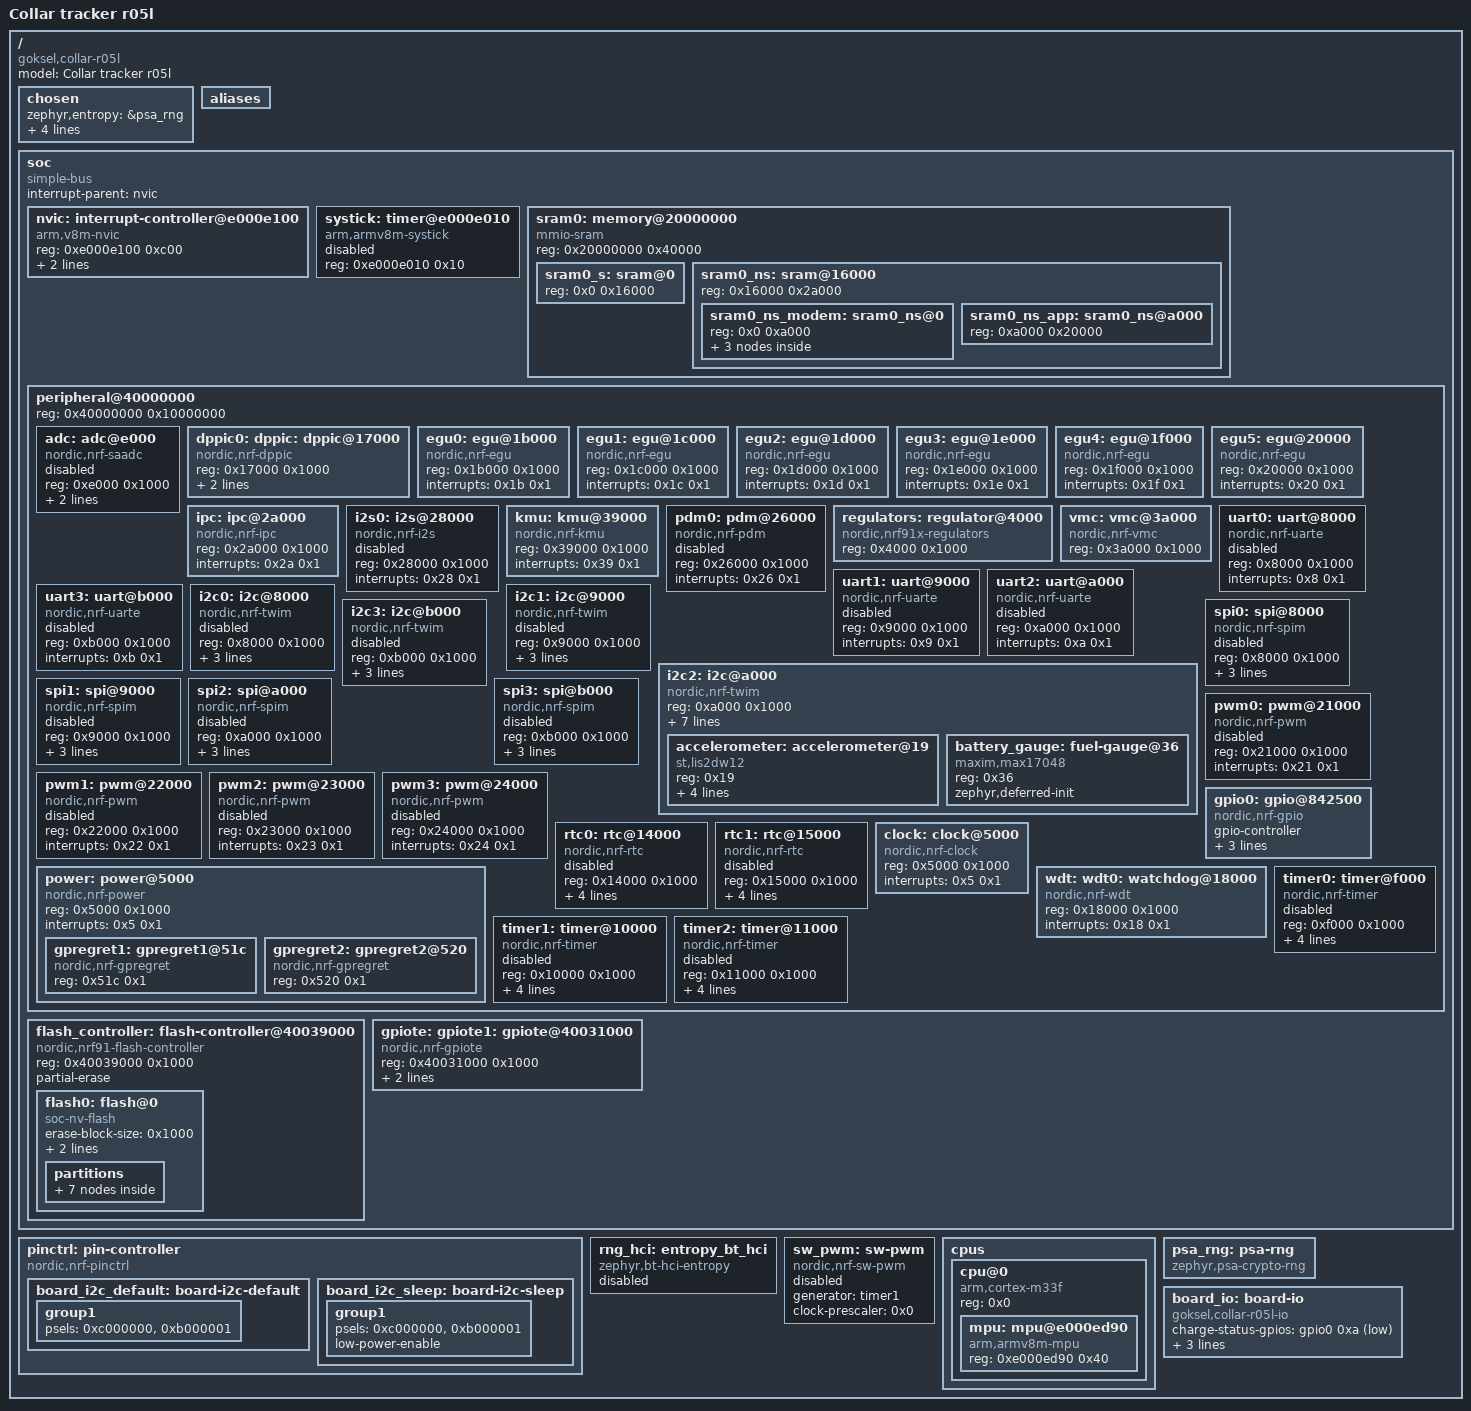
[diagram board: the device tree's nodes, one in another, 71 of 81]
/dts-v1/;

/* node '/' defined in zephyr/dts/common/skeleton.dtsi:9 */
/ {
	#address-cells = < 0x1 >;          /* in zephyr/dts/common/skeleton.dtsi:10 */
	#size-cells = < 0x1 >;             /* in zephyr/dts/common/skeleton.dtsi:11 */
	model = "Collar tracker r05l";     /* in ../../../../../Users/gok/codex/projects/collar-tracker/firmware/boards/goksel/collar_tracker_r05l/collar_tracker_r05l_nrf9151_ns.dts:7 */
	compatible = "goksel,collar-r05l"; /* in ../../../../../Users/gok/codex/projects/collar-tracker/firmware/boards/goksel/collar_tracker_r05l/collar_tracker_r05l_nrf9151_ns.dts:8 */

	/* node '/chosen' defined in zephyr/dts/common/skeleton.dtsi:13 */
	chosen {
		zephyr,entropy = &psa_rng;                   /* in zephyr/dts/arm/nordic/nrf91_ns.dtsi:31 */
		zephyr,flash-controller = &flash_controller; /* in zephyr/dts/arm/nordic/nrf91_ns.dtsi:32 */
		zephyr,sram = &sram0_ns_app;                 /* in ../../../../../Users/gok/codex/projects/collar-tracker/firmware/boards/goksel/collar_tracker_r05l/collar_tracker_r05l_nrf9151_ns.dts:10 */
		zephyr,code-partition = &slot0_ns_partition; /* in ../../../../../Users/gok/codex/projects/collar-tracker/firmware/boards/goksel/collar_tracker_r05l/collar_tracker_r05l_nrf9151_ns.dts:11 */
		zephyr,flash = &flash0;                      /* in ../../../../../Users/gok/codex/projects/collar-tracker/firmware/boards/goksel/collar_tracker_r05l/collar_tracker_r05l_nrf9151_ns.dts:12 */
	};

	/* node '/aliases' defined in zephyr/dts/common/skeleton.dtsi:15 */
	aliases {
	};

	/* node '/soc' defined in zephyr/dts/arm/armv8-m.dtsi:6 */
	soc {
		#address-cells = < 0x1 >;     /* in zephyr/dts/arm/armv8-m.dtsi:7 */
		#size-cells = < 0x1 >;        /* in zephyr/dts/arm/armv8-m.dtsi:8 */
		interrupt-parent = < &nvic >; /* in zephyr/dts/arm/armv8-m.dtsi:10 */
		ranges;                       /* in zephyr/dts/arm/armv8-m.dtsi:11 */
		compatible = "simple-bus";    /* in zephyr/dts/arm/nordic/nrf91_ns.dtsi:36 */

		/* node '/soc/interrupt-controller@e000e100' defined in zephyr/dts/arm/armv8-m.dtsi:13 */
		nvic: interrupt-controller@e000e100 {
			#address-cells = < 0x1 >;            /* in zephyr/dts/arm/armv8-m.dtsi:14 */
			compatible = "arm,v8m-nvic";         /* in zephyr/dts/arm/armv8-m.dtsi:15 */
			reg = < 0xe000e100 0xc00 >;          /* in zephyr/dts/arm/armv8-m.dtsi:16 */
			interrupt-controller;                /* in zephyr/dts/arm/armv8-m.dtsi:17 */
			#interrupt-cells = < 0x2 >;          /* in zephyr/dts/arm/armv8-m.dtsi:18 */
			arm,num-irq-priority-bits = < 0x3 >; /* in zephyr/dts/arm/nordic/nrf91_ns.dtsi:95 */
			phandle = < 0x1 >;                   /* in zephyr/dts/arm/armv8-m.dtsi:10 */
		};

		/* node '/soc/timer@e000e010' defined in zephyr/dts/arm/armv8-m.dtsi:21 */
		systick: timer@e000e010 {
			compatible = "arm,armv8m-systick"; /* in zephyr/dts/arm/armv8-m.dtsi:22 */
			reg = < 0xe000e010 0x10 >;         /* in zephyr/dts/arm/armv8-m.dtsi:23 */
			status = "disabled";               /* in zephyr/dts/arm/nordic/nrf91_ns.dtsi:100 */
		};

		/* node '/soc/memory@20000000' defined in zephyr/dts/arm/nordic/nrf91_ns.dtsi:38 */
		sram0: memory@20000000 {
			compatible = "mmio-sram";            /* in zephyr/dts/arm/nordic/nrf91_ns.dtsi:39 */
			#address-cells = < 0x1 >;            /* in zephyr/dts/arm/nordic/nrf91_ns.dtsi:40 */
			#size-cells = < 0x1 >;               /* in zephyr/dts/arm/nordic/nrf91_ns.dtsi:41 */
			reg = < 0x20000000 0x40000 >;        /* in zephyr/dts/arm/nordic/nrf9151_ns_laca.dtsi:11 */
			ranges = < 0x0 0x20000000 0x40000 >; /* in zephyr/dts/arm/nordic/nrf9151_ns_laca.dtsi:12 */

			/* node '/soc/memory@20000000/sram@0' defined in ../../../../../Users/gok/codex/projects/collar-tracker/firmware/boards/goksel/collar_tracker_r05l/collar-memory.dtsi:69 */
			sram0_s: sram@0 {
				reg = < 0x0 0x16000 >; /* in ../../../../../Users/gok/codex/projects/collar-tracker/firmware/boards/goksel/collar_tracker_r05l/collar-memory.dtsi:71 */
			};

			/* node '/soc/memory@20000000/sram@16000' defined in ../../../../../Users/gok/codex/projects/collar-tracker/firmware/boards/goksel/collar_tracker_r05l/collar-memory.dtsi:74 */
			sram0_ns: sram@16000 {
				reg = < 0x16000 0x2a000 >;        /* in ../../../../../Users/gok/codex/projects/collar-tracker/firmware/boards/goksel/collar_tracker_r05l/collar-memory.dtsi:76 */
				#address-cells = < 0x1 >;         /* in ../../../../../Users/gok/codex/projects/collar-tracker/firmware/boards/goksel/collar_tracker_r05l/collar-memory.dtsi:77 */
				#size-cells = < 0x1 >;            /* in ../../../../../Users/gok/codex/projects/collar-tracker/firmware/boards/goksel/collar_tracker_r05l/collar-memory.dtsi:78 */
				ranges = < 0x0 0x16000 0x2a000 >; /* in ../../../../../Users/gok/codex/projects/collar-tracker/firmware/boards/goksel/collar_tracker_r05l/collar-memory.dtsi:79 */

				/* node '/soc/memory@20000000/sram@16000/sram0_ns@0' defined in ../../../../../Users/gok/codex/projects/collar-tracker/firmware/boards/goksel/collar_tracker_r05l/collar-memory.dtsi:81 */
				sram0_ns_modem: sram0_ns@0 {
					reg = < 0x0 0xa000 >;        /* in ../../../../../Users/gok/codex/projects/collar-tracker/firmware/boards/goksel/collar_tracker_r05l/collar-memory.dtsi:83 */
					#address-cells = < 0x1 >;    /* in ../../../../../Users/gok/codex/projects/collar-tracker/firmware/boards/goksel/collar_tracker_r05l/collar-memory.dtsi:84 */
					#size-cells = < 0x1 >;       /* in ../../../../../Users/gok/codex/projects/collar-tracker/firmware/boards/goksel/collar_tracker_r05l/collar-memory.dtsi:85 */
					ranges = < 0x0 0x0 0xa000 >; /* in ../../../../../Users/gok/codex/projects/collar-tracker/firmware/boards/goksel/collar_tracker_r05l/collar-memory.dtsi:86 */

					/* node '/soc/memory@20000000/sram@16000/sram0_ns@0/sram0_ns_modem@0' defined in ../../../../../Users/gok/codex/projects/collar-tracker/firmware/boards/goksel/collar_tracker_r05l/collar-memory.dtsi:88 */
					cpuapp_cpucell_ipc_shm_ctrl: sram0_ns_modem@0 {
						reg = < 0x0 0x4e8 >; /* in ../../../../../Users/gok/codex/projects/collar-tracker/firmware/boards/goksel/collar_tracker_r05l/collar-memory.dtsi:90 */
					};

					/* node '/soc/memory@20000000/sram@16000/sram0_ns@0/sram0_ns_modem@4e8' defined in ../../../../../Users/gok/codex/projects/collar-tracker/firmware/boards/goksel/collar_tracker_r05l/collar-memory.dtsi:93 */
					cpuapp_cpucell_ipc_shm_heap: sram0_ns_modem@4e8 {
						reg = < 0x4e8 0x2080 >; /* in ../../../../../Users/gok/codex/projects/collar-tracker/firmware/boards/goksel/collar_tracker_r05l/collar-memory.dtsi:95 */
					};

					/* node '/soc/memory@20000000/sram@16000/sram0_ns@0/sram0_ns_modem@2568' defined in ../../../../../Users/gok/codex/projects/collar-tracker/firmware/boards/goksel/collar_tracker_r05l/collar-memory.dtsi:98 */
					cpucell_cpuapp_ipc_shm_heap: sram0_ns_modem@2568 {
						reg = < 0x2568 0x2000 >; /* in ../../../../../Users/gok/codex/projects/collar-tracker/firmware/boards/goksel/collar_tracker_r05l/collar-memory.dtsi:100 */
					};
				};

				/* node '/soc/memory@20000000/sram@16000/sram0_ns@a000' defined in ../../../../../Users/gok/codex/projects/collar-tracker/firmware/boards/goksel/collar_tracker_r05l/collar-memory.dtsi:104 */
				sram0_ns_app: sram0_ns@a000 {
					reg = < 0xa000 0x20000 >; /* in ../../../../../Users/gok/codex/projects/collar-tracker/firmware/boards/goksel/collar_tracker_r05l/collar-memory.dtsi:106 */
				};
			};
		};

		/* node '/soc/peripheral@40000000' defined in zephyr/dts/arm/nordic/nrf91_ns.dtsi:44 */
		peripheral@40000000 {
			#address-cells = < 0x1 >;               /* in zephyr/dts/arm/nordic/nrf91_ns.dtsi:45 */
			#size-cells = < 0x1 >;                  /* in zephyr/dts/arm/nordic/nrf91_ns.dtsi:46 */
			reg = < 0x40000000 0x10000000 >;        /* in zephyr/dts/arm/nordic/nrf91_ns.dtsi:47 */
			ranges = < 0x0 0x40000000 0x10000000 >; /* in zephyr/dts/arm/nordic/nrf91_ns.dtsi:48 */

			/* node '/soc/peripheral@40000000/adc@e000' defined in zephyr/dts/arm/nordic/nrf91_peripherals.dtsi:7 */
			adc: adc@e000 {
				compatible = "nordic,nrf-saadc"; /* in zephyr/dts/arm/nordic/nrf91_peripherals.dtsi:8 */
				reg = < 0xe000 0x1000 >;         /* in zephyr/dts/arm/nordic/nrf91_peripherals.dtsi:9 */
				interrupts = < 0xe 0x1 >;        /* in zephyr/dts/arm/nordic/nrf91_peripherals.dtsi:10 */
				status = "disabled";             /* in zephyr/dts/arm/nordic/nrf91_peripherals.dtsi:11 */
				#io-channel-cells = < 0x1 >;     /* in zephyr/dts/arm/nordic/nrf91_peripherals.dtsi:12 */
				zephyr,pm-device-runtime-auto;   /* in zephyr/dts/arm/nordic/nrf91_peripherals.dtsi:13 */
			};

			/* node '/soc/peripheral@40000000/dppic@17000' defined in zephyr/dts/arm/nordic/nrf91_peripherals.dtsi:16 */
			dppic0: dppic: dppic@17000 {
				compatible = "nordic,nrf-dppic"; /* in zephyr/dts/arm/nordic/nrf91_peripherals.dtsi:17 */
				reg = < 0x17000 0x1000 >;        /* in zephyr/dts/arm/nordic/nrf91_peripherals.dtsi:18 */
				status = "okay";                 /* in zephyr/dts/arm/nordic/nrf91_peripherals.dtsi:19 */
				channels = < 0x10 >;             /* in zephyr/dts/arm/nordic/nrf91_peripherals.dtsi:20 */
				groups = < 0x6 >;                /* in zephyr/dts/arm/nordic/nrf91_peripherals.dtsi:21 */
			};

			/* node '/soc/peripheral@40000000/egu@1b000' defined in zephyr/dts/arm/nordic/nrf91_peripherals.dtsi:24 */
			egu0: egu@1b000 {
				compatible = "nordic,nrf-egu"; /* in zephyr/dts/arm/nordic/nrf91_peripherals.dtsi:25 */
				reg = < 0x1b000 0x1000 >;      /* in zephyr/dts/arm/nordic/nrf91_peripherals.dtsi:26 */
				interrupts = < 0x1b 0x1 >;     /* in zephyr/dts/arm/nordic/nrf91_peripherals.dtsi:27 */
				status = "okay";               /* in zephyr/dts/arm/nordic/nrf91_peripherals.dtsi:28 */
			};

			/* node '/soc/peripheral@40000000/egu@1c000' defined in zephyr/dts/arm/nordic/nrf91_peripherals.dtsi:31 */
			egu1: egu@1c000 {
				compatible = "nordic,nrf-egu"; /* in zephyr/dts/arm/nordic/nrf91_peripherals.dtsi:32 */
				reg = < 0x1c000 0x1000 >;      /* in zephyr/dts/arm/nordic/nrf91_peripherals.dtsi:33 */
				interrupts = < 0x1c 0x1 >;     /* in zephyr/dts/arm/nordic/nrf91_peripherals.dtsi:34 */
				status = "okay";               /* in zephyr/dts/arm/nordic/nrf91_peripherals.dtsi:35 */
			};

			/* node '/soc/peripheral@40000000/egu@1d000' defined in zephyr/dts/arm/nordic/nrf91_peripherals.dtsi:38 */
			egu2: egu@1d000 {
				compatible = "nordic,nrf-egu"; /* in zephyr/dts/arm/nordic/nrf91_peripherals.dtsi:39 */
				reg = < 0x1d000 0x1000 >;      /* in zephyr/dts/arm/nordic/nrf91_peripherals.dtsi:40 */
				interrupts = < 0x1d 0x1 >;     /* in zephyr/dts/arm/nordic/nrf91_peripherals.dtsi:41 */
				status = "okay";               /* in zephyr/dts/arm/nordic/nrf91_peripherals.dtsi:42 */
			};

			/* node '/soc/peripheral@40000000/egu@1e000' defined in zephyr/dts/arm/nordic/nrf91_peripherals.dtsi:45 */
			egu3: egu@1e000 {
				compatible = "nordic,nrf-egu"; /* in zephyr/dts/arm/nordic/nrf91_peripherals.dtsi:46 */
				reg = < 0x1e000 0x1000 >;      /* in zephyr/dts/arm/nordic/nrf91_peripherals.dtsi:47 */
				interrupts = < 0x1e 0x1 >;     /* in zephyr/dts/arm/nordic/nrf91_peripherals.dtsi:48 */
				status = "okay";               /* in zephyr/dts/arm/nordic/nrf91_peripherals.dtsi:49 */
			};

			/* node '/soc/peripheral@40000000/egu@1f000' defined in zephyr/dts/arm/nordic/nrf91_peripherals.dtsi:52 */
			egu4: egu@1f000 {
				compatible = "nordic,nrf-egu"; /* in zephyr/dts/arm/nordic/nrf91_peripherals.dtsi:53 */
				reg = < 0x1f000 0x1000 >;      /* in zephyr/dts/arm/nordic/nrf91_peripherals.dtsi:54 */
				interrupts = < 0x1f 0x1 >;     /* in zephyr/dts/arm/nordic/nrf91_peripherals.dtsi:55 */
				status = "okay";               /* in zephyr/dts/arm/nordic/nrf91_peripherals.dtsi:56 */
			};

			/* node '/soc/peripheral@40000000/egu@20000' defined in zephyr/dts/arm/nordic/nrf91_peripherals.dtsi:59 */
			egu5: egu@20000 {
				compatible = "nordic,nrf-egu"; /* in zephyr/dts/arm/nordic/nrf91_peripherals.dtsi:60 */
				reg = < 0x20000 0x1000 >;      /* in zephyr/dts/arm/nordic/nrf91_peripherals.dtsi:61 */
				interrupts = < 0x20 0x1 >;     /* in zephyr/dts/arm/nordic/nrf91_peripherals.dtsi:62 */
				status = "okay";               /* in zephyr/dts/arm/nordic/nrf91_peripherals.dtsi:63 */
			};

			/* node '/soc/peripheral@40000000/ipc@2a000' defined in zephyr/dts/arm/nordic/nrf91_peripherals.dtsi:66 */
			ipc: ipc@2a000 {
				compatible = "nordic,nrf-ipc"; /* in zephyr/dts/arm/nordic/nrf91_peripherals.dtsi:67 */
				reg = < 0x2a000 0x1000 >;      /* in zephyr/dts/arm/nordic/nrf91_peripherals.dtsi:68 */
				interrupts = < 0x2a 0x1 >;     /* in zephyr/dts/arm/nordic/nrf91_peripherals.dtsi:69 */
				status = "okay";               /* in zephyr/dts/arm/nordic/nrf91_peripherals.dtsi:70 */
			};

			/* node '/soc/peripheral@40000000/i2s@28000' defined in zephyr/dts/arm/nordic/nrf91_peripherals.dtsi:73 */
			i2s0: i2s@28000 {
				compatible = "nordic,nrf-i2s"; /* in zephyr/dts/arm/nordic/nrf91_peripherals.dtsi:74 */
				#address-cells = < 0x1 >;      /* in zephyr/dts/arm/nordic/nrf91_peripherals.dtsi:75 */
				#size-cells = < 0x0 >;         /* in zephyr/dts/arm/nordic/nrf91_peripherals.dtsi:76 */
				reg = < 0x28000 0x1000 >;      /* in zephyr/dts/arm/nordic/nrf91_peripherals.dtsi:77 */
				interrupts = < 0x28 0x1 >;     /* in zephyr/dts/arm/nordic/nrf91_peripherals.dtsi:78 */
				status = "disabled";           /* in zephyr/dts/arm/nordic/nrf91_peripherals.dtsi:79 */
			};

			/* node '/soc/peripheral@40000000/kmu@39000' defined in zephyr/dts/arm/nordic/nrf91_peripherals.dtsi:82 */
			kmu: kmu@39000 {
				compatible = "nordic,nrf-kmu"; /* in zephyr/dts/arm/nordic/nrf91_peripherals.dtsi:83 */
				reg = < 0x39000 0x1000 >;      /* in zephyr/dts/arm/nordic/nrf91_peripherals.dtsi:84 */
				interrupts = < 0x39 0x1 >;     /* in zephyr/dts/arm/nordic/nrf91_peripherals.dtsi:85 */
				status = "okay";               /* in zephyr/dts/arm/nordic/nrf91_peripherals.dtsi:86 */
			};

			/* node '/soc/peripheral@40000000/pdm@26000' defined in zephyr/dts/arm/nordic/nrf91_peripherals.dtsi:89 */
			pdm0: pdm@26000 {
				compatible = "nordic,nrf-pdm"; /* in zephyr/dts/arm/nordic/nrf91_peripherals.dtsi:90 */
				reg = < 0x26000 0x1000 >;      /* in zephyr/dts/arm/nordic/nrf91_peripherals.dtsi:91 */
				interrupts = < 0x26 0x1 >;     /* in zephyr/dts/arm/nordic/nrf91_peripherals.dtsi:92 */
				status = "disabled";           /* in zephyr/dts/arm/nordic/nrf91_peripherals.dtsi:93 */
			};

			/* node '/soc/peripheral@40000000/regulator@4000' defined in zephyr/dts/arm/nordic/nrf91_peripherals.dtsi:96 */
			regulators: regulator@4000 {
				compatible = "nordic,nrf91x-regulators"; /* in zephyr/dts/arm/nordic/nrf91_peripherals.dtsi:97 */
				reg = < 0x4000 0x1000 >;                 /* in zephyr/dts/arm/nordic/nrf91_peripherals.dtsi:98 */
				status = "okay";                         /* in zephyr/dts/arm/nordic/nrf91_peripherals.dtsi:99 */
			};

			/* node '/soc/peripheral@40000000/vmc@3a000' defined in zephyr/dts/arm/nordic/nrf91_peripherals.dtsi:102 */
			vmc: vmc@3a000 {
				compatible = "nordic,nrf-vmc"; /* in zephyr/dts/arm/nordic/nrf91_peripherals.dtsi:103 */
				reg = < 0x3a000 0x1000 >;      /* in zephyr/dts/arm/nordic/nrf91_peripherals.dtsi:104 */
				status = "okay";               /* in zephyr/dts/arm/nordic/nrf91_peripherals.dtsi:105 */
			};

			/* node '/soc/peripheral@40000000/uart@8000' defined in zephyr/dts/arm/nordic/nrf91_peripherals.dtsi:108 */
			uart0: uart@8000 {
				compatible = "nordic,nrf-uarte"; /* in zephyr/dts/arm/nordic/nrf91_peripherals.dtsi:109 */
				reg = < 0x8000 0x1000 >;         /* in zephyr/dts/arm/nordic/nrf91_peripherals.dtsi:110 */
				interrupts = < 0x8 0x1 >;        /* in zephyr/dts/arm/nordic/nrf91_peripherals.dtsi:111 */
				status = "disabled";             /* in zephyr/dts/arm/nordic/nrf91_peripherals.dtsi:112 */
			};

			/* node '/soc/peripheral@40000000/uart@9000' defined in zephyr/dts/arm/nordic/nrf91_peripherals.dtsi:115 */
			uart1: uart@9000 {
				compatible = "nordic,nrf-uarte"; /* in zephyr/dts/arm/nordic/nrf91_peripherals.dtsi:116 */
				reg = < 0x9000 0x1000 >;         /* in zephyr/dts/arm/nordic/nrf91_peripherals.dtsi:117 */
				interrupts = < 0x9 0x1 >;        /* in zephyr/dts/arm/nordic/nrf91_peripherals.dtsi:118 */
				status = "disabled";             /* in zephyr/dts/arm/nordic/nrf91_peripherals.dtsi:119 */
			};

			/* node '/soc/peripheral@40000000/uart@a000' defined in zephyr/dts/arm/nordic/nrf91_peripherals.dtsi:122 */
			uart2: uart@a000 {
				compatible = "nordic,nrf-uarte"; /* in zephyr/dts/arm/nordic/nrf91_peripherals.dtsi:123 */
				reg = < 0xa000 0x1000 >;         /* in zephyr/dts/arm/nordic/nrf91_peripherals.dtsi:124 */
				interrupts = < 0xa 0x1 >;        /* in zephyr/dts/arm/nordic/nrf91_peripherals.dtsi:125 */
				status = "disabled";             /* in zephyr/dts/arm/nordic/nrf91_peripherals.dtsi:126 */
			};

			/* node '/soc/peripheral@40000000/uart@b000' defined in zephyr/dts/arm/nordic/nrf91_peripherals.dtsi:129 */
			uart3: uart@b000 {
				compatible = "nordic,nrf-uarte"; /* in zephyr/dts/arm/nordic/nrf91_peripherals.dtsi:130 */
				reg = < 0xb000 0x1000 >;         /* in zephyr/dts/arm/nordic/nrf91_peripherals.dtsi:131 */
				interrupts = < 0xb 0x1 >;        /* in zephyr/dts/arm/nordic/nrf91_peripherals.dtsi:132 */
				status = "disabled";             /* in zephyr/dts/arm/nordic/nrf91_peripherals.dtsi:133 */
			};

			/* node '/soc/peripheral@40000000/i2c@8000' defined in zephyr/dts/arm/nordic/nrf91_peripherals.dtsi:136 */
			i2c0: i2c@8000 {
				compatible = "nordic,nrf-twim"; /* in zephyr/dts/arm/nordic/nrf91_peripherals.dtsi:142 */
				#address-cells = < 0x1 >;       /* in zephyr/dts/arm/nordic/nrf91_peripherals.dtsi:143 */
				#size-cells = < 0x0 >;          /* in zephyr/dts/arm/nordic/nrf91_peripherals.dtsi:144 */
				reg = < 0x8000 0x1000 >;        /* in zephyr/dts/arm/nordic/nrf91_peripherals.dtsi:145 */
				interrupts = < 0x8 0x1 >;       /* in zephyr/dts/arm/nordic/nrf91_peripherals.dtsi:146 */
				easydma-maxcnt-bits = < 0xd >;  /* in zephyr/dts/arm/nordic/nrf91_peripherals.dtsi:147 */
				status = "disabled";            /* in zephyr/dts/arm/nordic/nrf91_peripherals.dtsi:148 */
				zephyr,pm-device-runtime-auto;  /* in zephyr/dts/arm/nordic/nrf91_peripherals.dtsi:149 */
			};

			/* node '/soc/peripheral@40000000/i2c@9000' defined in zephyr/dts/arm/nordic/nrf91_peripherals.dtsi:152 */
			i2c1: i2c@9000 {
				compatible = "nordic,nrf-twim"; /* in zephyr/dts/arm/nordic/nrf91_peripherals.dtsi:158 */
				#address-cells = < 0x1 >;       /* in zephyr/dts/arm/nordic/nrf91_peripherals.dtsi:159 */
				#size-cells = < 0x0 >;          /* in zephyr/dts/arm/nordic/nrf91_peripherals.dtsi:160 */
				reg = < 0x9000 0x1000 >;        /* in zephyr/dts/arm/nordic/nrf91_peripherals.dtsi:161 */
				interrupts = < 0x9 0x1 >;       /* in zephyr/dts/arm/nordic/nrf91_peripherals.dtsi:162 */
				easydma-maxcnt-bits = < 0xd >;  /* in zephyr/dts/arm/nordic/nrf91_peripherals.dtsi:163 */
				status = "disabled";            /* in zephyr/dts/arm/nordic/nrf91_peripherals.dtsi:164 */
				zephyr,pm-device-runtime-auto;  /* in zephyr/dts/arm/nordic/nrf91_peripherals.dtsi:165 */
			};

			/* node '/soc/peripheral@40000000/i2c@a000' defined in zephyr/dts/arm/nordic/nrf91_peripherals.dtsi:168 */
			i2c2: i2c@a000 {
				#address-cells = < 0x1 >;           /* in zephyr/dts/arm/nordic/nrf91_peripherals.dtsi:175 */
				#size-cells = < 0x0 >;              /* in zephyr/dts/arm/nordic/nrf91_peripherals.dtsi:176 */
				reg = < 0xa000 0x1000 >;            /* in zephyr/dts/arm/nordic/nrf91_peripherals.dtsi:177 */
				interrupts = < 0xa 0x1 >;           /* in zephyr/dts/arm/nordic/nrf91_peripherals.dtsi:178 */
				easydma-maxcnt-bits = < 0xd >;      /* in zephyr/dts/arm/nordic/nrf91_peripherals.dtsi:179 */
				zephyr,pm-device-runtime-auto;      /* in zephyr/dts/arm/nordic/nrf91_peripherals.dtsi:181 */
				compatible = "nordic,nrf-twim";     /* in ../../../../../Users/gok/codex/projects/collar-tracker/firmware/boards/goksel/collar_tracker_r05l/collar_tracker_r05l_nrf9151_ns.dts:40 */
				status = "okay";                    /* in ../../../../../Users/gok/codex/projects/collar-tracker/firmware/boards/goksel/collar_tracker_r05l/collar_tracker_r05l_nrf9151_ns.dts:41 */
				zephyr,deferred-init;               /* in ../../../../../Users/gok/codex/projects/collar-tracker/firmware/boards/goksel/collar_tracker_r05l/collar_tracker_r05l_nrf9151_ns.dts:42 */
				clock-frequency = < 0x186a0 >;      /* in ../../../../../Users/gok/codex/projects/collar-tracker/firmware/boards/goksel/collar_tracker_r05l/collar_tracker_r05l_nrf9151_ns.dts:43 */
				pinctrl-0 = < &board_i2c_default >; /* in ../../../../../Users/gok/codex/projects/collar-tracker/firmware/boards/goksel/collar_tracker_r05l/collar_tracker_r05l_nrf9151_ns.dts:44 */
				pinctrl-1 = < &board_i2c_sleep >;   /* in ../../../../../Users/gok/codex/projects/collar-tracker/firmware/boards/goksel/collar_tracker_r05l/collar_tracker_r05l_nrf9151_ns.dts:45 */
				pinctrl-names = "default",
				                "sleep";            /* in ../../../../../Users/gok/codex/projects/collar-tracker/firmware/boards/goksel/collar_tracker_r05l/collar_tracker_r05l_nrf9151_ns.dts:46 */

				/* node '/soc/peripheral@40000000/i2c@a000/accelerometer@19' defined in ../../../../../Users/gok/codex/projects/collar-tracker/firmware/boards/goksel/collar_tracker_r05l/collar_tracker_r05l_nrf9151_ns.dts:47 */
				accelerometer: accelerometer@19 {
					compatible = "st,lis2dw12";     /* in ../../../../../Users/gok/codex/projects/collar-tracker/firmware/boards/goksel/collar_tracker_r05l/collar_tracker_r05l_nrf9151_ns.dts:48 */
					reg = < 0x19 >;                 /* in ../../../../../Users/gok/codex/projects/collar-tracker/firmware/boards/goksel/collar_tracker_r05l/collar_tracker_r05l_nrf9151_ns.dts:49 */
					zephyr,deferred-init;           /* in ../../../../../Users/gok/codex/projects/collar-tracker/firmware/boards/goksel/collar_tracker_r05l/collar_tracker_r05l_nrf9151_ns.dts:50 */
					range = < 0x2 >;                /* in ../../../../../Users/gok/codex/projects/collar-tracker/firmware/boards/goksel/collar_tracker_r05l/collar_tracker_r05l_nrf9151_ns.dts:51 */
					odr = < 0x19 >;                 /* in ../../../../../Users/gok/codex/projects/collar-tracker/firmware/boards/goksel/collar_tracker_r05l/collar_tracker_r05l_nrf9151_ns.dts:52 */
					irq-gpios = < &gpio0 0x2 0x0 >; /* in ../../../../../Users/gok/codex/projects/collar-tracker/firmware/boards/goksel/collar_tracker_r05l/collar_tracker_r05l_nrf9151_ns.dts:53 */
				};

				/* node '/soc/peripheral@40000000/i2c@a000/fuel-gauge@36' defined in ../../../../../Users/gok/codex/projects/collar-tracker/firmware/boards/goksel/collar_tracker_r05l/collar_tracker_r05l_nrf9151_ns.dts:56 */
				battery_gauge: fuel-gauge@36 {
					compatible = "maxim,max17048"; /* in ../../../../../Users/gok/codex/projects/collar-tracker/firmware/boards/goksel/collar_tracker_r05l/collar_tracker_r05l_nrf9151_ns.dts:57 */
					reg = < 0x36 >;                /* in ../../../../../Users/gok/codex/projects/collar-tracker/firmware/boards/goksel/collar_tracker_r05l/collar_tracker_r05l_nrf9151_ns.dts:58 */
					zephyr,deferred-init;          /* in ../../../../../Users/gok/codex/projects/collar-tracker/firmware/boards/goksel/collar_tracker_r05l/collar_tracker_r05l_nrf9151_ns.dts:59 */
				};
			};

			/* node '/soc/peripheral@40000000/i2c@b000' defined in zephyr/dts/arm/nordic/nrf91_peripherals.dtsi:184 */
			i2c3: i2c@b000 {
				compatible = "nordic,nrf-twim"; /* in zephyr/dts/arm/nordic/nrf91_peripherals.dtsi:190 */
				#address-cells = < 0x1 >;       /* in zephyr/dts/arm/nordic/nrf91_peripherals.dtsi:191 */
				#size-cells = < 0x0 >;          /* in zephyr/dts/arm/nordic/nrf91_peripherals.dtsi:192 */
				reg = < 0xb000 0x1000 >;        /* in zephyr/dts/arm/nordic/nrf91_peripherals.dtsi:193 */
				interrupts = < 0xb 0x1 >;       /* in zephyr/dts/arm/nordic/nrf91_peripherals.dtsi:194 */
				easydma-maxcnt-bits = < 0xd >;  /* in zephyr/dts/arm/nordic/nrf91_peripherals.dtsi:195 */
				status = "disabled";            /* in zephyr/dts/arm/nordic/nrf91_peripherals.dtsi:196 */
				zephyr,pm-device-runtime-auto;  /* in zephyr/dts/arm/nordic/nrf91_peripherals.dtsi:197 */
			};

			/* node '/soc/peripheral@40000000/spi@8000' defined in zephyr/dts/arm/nordic/nrf91_peripherals.dtsi:200 */
			spi0: spi@8000 {
				compatible = "nordic,nrf-spim"; /* in zephyr/dts/arm/nordic/nrf91_peripherals.dtsi:206 */
				#address-cells = < 0x1 >;       /* in zephyr/dts/arm/nordic/nrf91_peripherals.dtsi:207 */
				#size-cells = < 0x0 >;          /* in zephyr/dts/arm/nordic/nrf91_peripherals.dtsi:208 */
				reg = < 0x8000 0x1000 >;        /* in zephyr/dts/arm/nordic/nrf91_peripherals.dtsi:209 */
				interrupts = < 0x8 0x1 >;       /* in zephyr/dts/arm/nordic/nrf91_peripherals.dtsi:210 */
				max-frequency = < 0x7a1200 >;   /* in zephyr/dts/arm/nordic/nrf91_peripherals.dtsi:211 */
				easydma-maxcnt-bits = < 0xd >;  /* in zephyr/dts/arm/nordic/nrf91_peripherals.dtsi:212 */
				status = "disabled";            /* in zephyr/dts/arm/nordic/nrf91_peripherals.dtsi:213 */
			};

			/* node '/soc/peripheral@40000000/spi@9000' defined in zephyr/dts/arm/nordic/nrf91_peripherals.dtsi:216 */
			spi1: spi@9000 {
				compatible = "nordic,nrf-spim"; /* in zephyr/dts/arm/nordic/nrf91_peripherals.dtsi:222 */
				#address-cells = < 0x1 >;       /* in zephyr/dts/arm/nordic/nrf91_peripherals.dtsi:223 */
				#size-cells = < 0x0 >;          /* in zephyr/dts/arm/nordic/nrf91_peripherals.dtsi:224 */
				reg = < 0x9000 0x1000 >;        /* in zephyr/dts/arm/nordic/nrf91_peripherals.dtsi:225 */
				interrupts = < 0x9 0x1 >;       /* in zephyr/dts/arm/nordic/nrf91_peripherals.dtsi:226 */
				max-frequency = < 0x7a1200 >;   /* in zephyr/dts/arm/nordic/nrf91_peripherals.dtsi:227 */
				easydma-maxcnt-bits = < 0xd >;  /* in zephyr/dts/arm/nordic/nrf91_peripherals.dtsi:228 */
				status = "disabled";            /* in zephyr/dts/arm/nordic/nrf91_peripherals.dtsi:229 */
			};

			/* node '/soc/peripheral@40000000/spi@a000' defined in zephyr/dts/arm/nordic/nrf91_peripherals.dtsi:232 */
			spi2: spi@a000 {
				compatible = "nordic,nrf-spim"; /* in zephyr/dts/arm/nordic/nrf91_peripherals.dtsi:238 */
				#address-cells = < 0x1 >;       /* in zephyr/dts/arm/nordic/nrf91_peripherals.dtsi:239 */
				#size-cells = < 0x0 >;          /* in zephyr/dts/arm/nordic/nrf91_peripherals.dtsi:240 */
				reg = < 0xa000 0x1000 >;        /* in zephyr/dts/arm/nordic/nrf91_peripherals.dtsi:241 */
				interrupts = < 0xa 0x1 >;       /* in zephyr/dts/arm/nordic/nrf91_peripherals.dtsi:242 */
				max-frequency = < 0x7a1200 >;   /* in zephyr/dts/arm/nordic/nrf91_peripherals.dtsi:243 */
				easydma-maxcnt-bits = < 0xd >;  /* in zephyr/dts/arm/nordic/nrf91_peripherals.dtsi:244 */
				status = "disabled";            /* in zephyr/dts/arm/nordic/nrf91_peripherals.dtsi:245 */
			};

			/* node '/soc/peripheral@40000000/spi@b000' defined in zephyr/dts/arm/nordic/nrf91_peripherals.dtsi:248 */
			spi3: spi@b000 {
				compatible = "nordic,nrf-spim"; /* in zephyr/dts/arm/nordic/nrf91_peripherals.dtsi:254 */
				#address-cells = < 0x1 >;       /* in zephyr/dts/arm/nordic/nrf91_peripherals.dtsi:255 */
				#size-cells = < 0x0 >;          /* in zephyr/dts/arm/nordic/nrf91_peripherals.dtsi:256 */
				reg = < 0xb000 0x1000 >;        /* in zephyr/dts/arm/nordic/nrf91_peripherals.dtsi:257 */
				interrupts = < 0xb 0x1 >;       /* in zephyr/dts/arm/nordic/nrf91_peripherals.dtsi:258 */
				max-frequency = < 0x7a1200 >;   /* in zephyr/dts/arm/nordic/nrf91_peripherals.dtsi:259 */
				easydma-maxcnt-bits = < 0xd >;  /* in zephyr/dts/arm/nordic/nrf91_peripherals.dtsi:260 */
				status = "disabled";            /* in zephyr/dts/arm/nordic/nrf91_peripherals.dtsi:261 */
			};

			/* node '/soc/peripheral@40000000/pwm@21000' defined in zephyr/dts/arm/nordic/nrf91_peripherals.dtsi:264 */
			pwm0: pwm@21000 {
				compatible = "nordic,nrf-pwm"; /* in zephyr/dts/arm/nordic/nrf91_peripherals.dtsi:265 */
				reg = < 0x21000 0x1000 >;      /* in zephyr/dts/arm/nordic/nrf91_peripherals.dtsi:266 */
				interrupts = < 0x21 0x1 >;     /* in zephyr/dts/arm/nordic/nrf91_peripherals.dtsi:267 */
				status = "disabled";           /* in zephyr/dts/arm/nordic/nrf91_peripherals.dtsi:268 */
				#pwm-cells = < 0x3 >;          /* in zephyr/dts/arm/nordic/nrf91_peripherals.dtsi:269 */
			};

			/* node '/soc/peripheral@40000000/pwm@22000' defined in zephyr/dts/arm/nordic/nrf91_peripherals.dtsi:272 */
			pwm1: pwm@22000 {
				compatible = "nordic,nrf-pwm"; /* in zephyr/dts/arm/nordic/nrf91_peripherals.dtsi:273 */
				reg = < 0x22000 0x1000 >;      /* in zephyr/dts/arm/nordic/nrf91_peripherals.dtsi:274 */
				interrupts = < 0x22 0x1 >;     /* in zephyr/dts/arm/nordic/nrf91_peripherals.dtsi:275 */
				status = "disabled";           /* in zephyr/dts/arm/nordic/nrf91_peripherals.dtsi:276 */
				#pwm-cells = < 0x3 >;          /* in zephyr/dts/arm/nordic/nrf91_peripherals.dtsi:277 */
			};

			/* node '/soc/peripheral@40000000/pwm@23000' defined in zephyr/dts/arm/nordic/nrf91_peripherals.dtsi:280 */
			pwm2: pwm@23000 {
				compatible = "nordic,nrf-pwm"; /* in zephyr/dts/arm/nordic/nrf91_peripherals.dtsi:281 */
				reg = < 0x23000 0x1000 >;      /* in zephyr/dts/arm/nordic/nrf91_peripherals.dtsi:282 */
				interrupts = < 0x23 0x1 >;     /* in zephyr/dts/arm/nordic/nrf91_peripherals.dtsi:283 */
				status = "disabled";           /* in zephyr/dts/arm/nordic/nrf91_peripherals.dtsi:284 */
				#pwm-cells = < 0x3 >;          /* in zephyr/dts/arm/nordic/nrf91_peripherals.dtsi:285 */
			};

			/* node '/soc/peripheral@40000000/pwm@24000' defined in zephyr/dts/arm/nordic/nrf91_peripherals.dtsi:288 */
			pwm3: pwm@24000 {
				compatible = "nordic,nrf-pwm"; /* in zephyr/dts/arm/nordic/nrf91_peripherals.dtsi:289 */
				reg = < 0x24000 0x1000 >;      /* in zephyr/dts/arm/nordic/nrf91_peripherals.dtsi:290 */
				interrupts = < 0x24 0x1 >;     /* in zephyr/dts/arm/nordic/nrf91_peripherals.dtsi:291 */
				status = "disabled";           /* in zephyr/dts/arm/nordic/nrf91_peripherals.dtsi:292 */
				#pwm-cells = < 0x3 >;          /* in zephyr/dts/arm/nordic/nrf91_peripherals.dtsi:293 */
			};

			/* node '/soc/peripheral@40000000/gpio@842500' defined in zephyr/dts/arm/nordic/nrf91_peripherals.dtsi:296 */
			gpio0: gpio@842500 {
				compatible = "nordic,nrf-gpio"; /* in zephyr/dts/arm/nordic/nrf91_peripherals.dtsi:297 */
				gpio-controller;                /* in zephyr/dts/arm/nordic/nrf91_peripherals.dtsi:298 */
				reg = < 0x842500 0x300 >;       /* in zephyr/dts/arm/nordic/nrf91_peripherals.dtsi:299 */
				#gpio-cells = < 0x2 >;          /* in zephyr/dts/arm/nordic/nrf91_peripherals.dtsi:300 */
				port = < 0x0 >;                 /* in zephyr/dts/arm/nordic/nrf91_peripherals.dtsi:302 */
				gpiote-instance = < &gpiote >;  /* in zephyr/dts/arm/nordic/nrf91_peripherals.dtsi:303 */
				status = "okay";                /* in ../../../../../Users/gok/codex/projects/collar-tracker/firmware/boards/goksel/collar_tracker_r05l/collar_tracker_r05l_nrf9151_ns.dts:23 */
				phandle = < 0x4 >;              /* in ../../../../../Users/gok/codex/projects/collar-tracker/firmware/boards/goksel/collar_tracker_r05l/collar_tracker_r05l_nrf9151_ns.dts:53 */
			};

			/* node '/soc/peripheral@40000000/rtc@14000' defined in zephyr/dts/arm/nordic/nrf91_peripherals.dtsi:306 */
			rtc0: rtc@14000 {
				compatible = "nordic,nrf-rtc"; /* in zephyr/dts/arm/nordic/nrf91_peripherals.dtsi:307 */
				reg = < 0x14000 0x1000 >;      /* in zephyr/dts/arm/nordic/nrf91_peripherals.dtsi:308 */
				cc-num = < 0x4 >;              /* in zephyr/dts/arm/nordic/nrf91_peripherals.dtsi:309 */
				interrupts = < 0x14 0x1 >;     /* in zephyr/dts/arm/nordic/nrf91_peripherals.dtsi:310 */
				status = "disabled";           /* in zephyr/dts/arm/nordic/nrf91_peripherals.dtsi:311 */
				clock-frequency = < 0x8000 >;  /* in zephyr/dts/arm/nordic/nrf91_peripherals.dtsi:312 */
				prescaler = < 0x1 >;           /* in zephyr/dts/arm/nordic/nrf91_peripherals.dtsi:313 */
			};

			/* node '/soc/peripheral@40000000/rtc@15000' defined in zephyr/dts/arm/nordic/nrf91_peripherals.dtsi:316 */
			rtc1: rtc@15000 {
				compatible = "nordic,nrf-rtc"; /* in zephyr/dts/arm/nordic/nrf91_peripherals.dtsi:317 */
				reg = < 0x15000 0x1000 >;      /* in zephyr/dts/arm/nordic/nrf91_peripherals.dtsi:318 */
				cc-num = < 0x4 >;              /* in zephyr/dts/arm/nordic/nrf91_peripherals.dtsi:319 */
				interrupts = < 0x15 0x1 >;     /* in zephyr/dts/arm/nordic/nrf91_peripherals.dtsi:320 */
				status = "disabled";           /* in zephyr/dts/arm/nordic/nrf91_peripherals.dtsi:321 */
				clock-frequency = < 0x8000 >;  /* in zephyr/dts/arm/nordic/nrf91_peripherals.dtsi:322 */
				prescaler = < 0x1 >;           /* in zephyr/dts/arm/nordic/nrf91_peripherals.dtsi:323 */
			};

			/* node '/soc/peripheral@40000000/clock@5000' defined in zephyr/dts/arm/nordic/nrf91_peripherals.dtsi:326 */
			clock: clock@5000 {
				compatible = "nordic,nrf-clock"; /* in zephyr/dts/arm/nordic/nrf91_peripherals.dtsi:327 */
				reg = < 0x5000 0x1000 >;         /* in zephyr/dts/arm/nordic/nrf91_peripherals.dtsi:328 */
				interrupts = < 0x5 0x1 >;        /* in zephyr/dts/arm/nordic/nrf91_peripherals.dtsi:329 */
				status = "okay";                 /* in zephyr/dts/arm/nordic/nrf91_peripherals.dtsi:330 */
			};

			/* node '/soc/peripheral@40000000/power@5000' defined in zephyr/dts/arm/nordic/nrf91_peripherals.dtsi:333 */
			power: power@5000 {
				compatible = "nordic,nrf-power"; /* in zephyr/dts/arm/nordic/nrf91_peripherals.dtsi:334 */
				reg = < 0x5000 0x1000 >;         /* in zephyr/dts/arm/nordic/nrf91_peripherals.dtsi:335 */
				ranges = < 0x0 0x5000 0x1000 >;  /* in zephyr/dts/arm/nordic/nrf91_peripherals.dtsi:336 */
				interrupts = < 0x5 0x1 >;        /* in zephyr/dts/arm/nordic/nrf91_peripherals.dtsi:337 */
				status = "okay";                 /* in zephyr/dts/arm/nordic/nrf91_peripherals.dtsi:338 */
				#address-cells = < 0x1 >;        /* in zephyr/dts/arm/nordic/nrf91_peripherals.dtsi:339 */
				#size-cells = < 0x1 >;           /* in zephyr/dts/arm/nordic/nrf91_peripherals.dtsi:340 */

				/* node '/soc/peripheral@40000000/power@5000/gpregret1@51c' defined in zephyr/dts/arm/nordic/nrf91_peripherals.dtsi:342 */
				gpregret1: gpregret1@51c {
					#address-cells = < 0x1 >;           /* in zephyr/dts/arm/nordic/nrf91_peripherals.dtsi:343 */
					#size-cells = < 0x1 >;              /* in zephyr/dts/arm/nordic/nrf91_peripherals.dtsi:344 */
					compatible = "nordic,nrf-gpregret"; /* in zephyr/dts/arm/nordic/nrf91_peripherals.dtsi:345 */
					reg = < 0x51c 0x1 >;                /* in zephyr/dts/arm/nordic/nrf91_peripherals.dtsi:346 */
					status = "okay";                    /* in zephyr/dts/arm/nordic/nrf91_peripherals.dtsi:347 */
				};

				/* node '/soc/peripheral@40000000/power@5000/gpregret2@520' defined in zephyr/dts/arm/nordic/nrf91_peripherals.dtsi:350 */
				gpregret2: gpregret2@520 {
					#address-cells = < 0x1 >;           /* in zephyr/dts/arm/nordic/nrf91_peripherals.dtsi:351 */
					#size-cells = < 0x1 >;              /* in zephyr/dts/arm/nordic/nrf91_peripherals.dtsi:352 */
					compatible = "nordic,nrf-gpregret"; /* in zephyr/dts/arm/nordic/nrf91_peripherals.dtsi:353 */
					reg = < 0x520 0x1 >;                /* in zephyr/dts/arm/nordic/nrf91_peripherals.dtsi:354 */
					status = "okay";                    /* in zephyr/dts/arm/nordic/nrf91_peripherals.dtsi:355 */
				};
			};

			/* node '/soc/peripheral@40000000/watchdog@18000' defined in zephyr/dts/arm/nordic/nrf91_peripherals.dtsi:359 */
			wdt: wdt0: watchdog@18000 {
				compatible = "nordic,nrf-wdt"; /* in zephyr/dts/arm/nordic/nrf91_peripherals.dtsi:360 */
				reg = < 0x18000 0x1000 >;      /* in zephyr/dts/arm/nordic/nrf91_peripherals.dtsi:361 */
				interrupts = < 0x18 0x1 >;     /* in zephyr/dts/arm/nordic/nrf91_peripherals.dtsi:362 */
				status = "okay";               /* in zephyr/dts/arm/nordic/nrf91_peripherals.dtsi:363 */
			};

			/* node '/soc/peripheral@40000000/timer@f000' defined in zephyr/dts/arm/nordic/nrf91_peripherals.dtsi:366 */
			timer0: timer@f000 {
				compatible = "nordic,nrf-timer"; /* in zephyr/dts/arm/nordic/nrf91_peripherals.dtsi:367 */
				status = "disabled";             /* in zephyr/dts/arm/nordic/nrf91_peripherals.dtsi:368 */
				reg = < 0xf000 0x1000 >;         /* in zephyr/dts/arm/nordic/nrf91_peripherals.dtsi:369 */
				cc-num = < 0x6 >;                /* in zephyr/dts/arm/nordic/nrf91_peripherals.dtsi:370 */
				max-bit-width = < 0x20 >;        /* in zephyr/dts/arm/nordic/nrf91_peripherals.dtsi:371 */
				interrupts = < 0xf 0x1 >;        /* in zephyr/dts/arm/nordic/nrf91_peripherals.dtsi:372 */
				prescaler = < 0x0 >;             /* in zephyr/dts/arm/nordic/nrf91_peripherals.dtsi:373 */
			};

			/* node '/soc/peripheral@40000000/timer@10000' defined in zephyr/dts/arm/nordic/nrf91_peripherals.dtsi:376 */
			timer1: timer@10000 {
				compatible = "nordic,nrf-timer"; /* in zephyr/dts/arm/nordic/nrf91_peripherals.dtsi:377 */
				status = "disabled";             /* in zephyr/dts/arm/nordic/nrf91_peripherals.dtsi:378 */
				reg = < 0x10000 0x1000 >;        /* in zephyr/dts/arm/nordic/nrf91_peripherals.dtsi:379 */
				cc-num = < 0x6 >;                /* in zephyr/dts/arm/nordic/nrf91_peripherals.dtsi:380 */
				max-bit-width = < 0x20 >;        /* in zephyr/dts/arm/nordic/nrf91_peripherals.dtsi:381 */
				interrupts = < 0x10 0x1 >;       /* in zephyr/dts/arm/nordic/nrf91_peripherals.dtsi:382 */
				prescaler = < 0x0 >;             /* in zephyr/dts/arm/nordic/nrf91_peripherals.dtsi:383 */
				phandle = < 0x6 >;               /* in zephyr/dts/vendor/nordic/nrf_common.dtsi:42 */
			};

			/* node '/soc/peripheral@40000000/timer@11000' defined in zephyr/dts/arm/nordic/nrf91_peripherals.dtsi:386 */
			timer2: timer@11000 {
				compatible = "nordic,nrf-timer"; /* in zephyr/dts/arm/nordic/nrf91_peripherals.dtsi:387 */
				status = "disabled";             /* in zephyr/dts/arm/nordic/nrf91_peripherals.dtsi:388 */
				reg = < 0x11000 0x1000 >;        /* in zephyr/dts/arm/nordic/nrf91_peripherals.dtsi:389 */
				cc-num = < 0x6 >;                /* in zephyr/dts/arm/nordic/nrf91_peripherals.dtsi:390 */
				max-bit-width = < 0x20 >;        /* in zephyr/dts/arm/nordic/nrf91_peripherals.dtsi:391 */
				interrupts = < 0x11 0x1 >;       /* in zephyr/dts/arm/nordic/nrf91_peripherals.dtsi:392 */
				prescaler = < 0x0 >;             /* in zephyr/dts/arm/nordic/nrf91_peripherals.dtsi:393 */
			};
		};

		/* node '/soc/flash-controller@40039000' defined in zephyr/dts/arm/nordic/nrf91_ns.dtsi:54 */
		flash_controller: flash-controller@40039000 {
			compatible = "nordic,nrf91-flash-controller"; /* in zephyr/dts/arm/nordic/nrf91_ns.dtsi:55 */
			reg = < 0x40039000 0x1000 >;                  /* in zephyr/dts/arm/nordic/nrf91_ns.dtsi:56 */
			ranges;                                       /* in zephyr/dts/arm/nordic/nrf91_ns.dtsi:57 */
			partial-erase;                                /* in zephyr/dts/arm/nordic/nrf91_ns.dtsi:58 */
			#address-cells = < 0x1 >;                     /* in zephyr/dts/arm/nordic/nrf91_ns.dtsi:59 */
			#size-cells = < 0x1 >;                        /* in zephyr/dts/arm/nordic/nrf91_ns.dtsi:60 */

			/* node '/soc/flash-controller@40039000/flash@0' defined in zephyr/dts/arm/nordic/nrf91_ns.dtsi:62 */
			flash0: flash@0 {
				compatible = "soc-nv-flash";   /* in zephyr/dts/arm/nordic/nrf91_ns.dtsi:63 */
				erase-block-size = < 0x1000 >; /* in zephyr/dts/arm/nordic/nrf91_ns.dtsi:64 */
				write-block-size = < 0x4 >;    /* in zephyr/dts/arm/nordic/nrf91_ns.dtsi:65 */
				reg = < 0x0 0x100000 >;        /* in zephyr/dts/arm/nordic/nrf91_ns.dtsi:66 */
				ranges = < 0x0 0x0 0x100000 >; /* in zephyr/dts/arm/nordic/nrf91_ns.dtsi:67 */
				status = "okay";               /* in zephyr/dts/arm/nordic/nrf91_ns.dtsi:68 */
				#address-cells = < 0x1 >;      /* in zephyr/dts/arm/nordic/nrf91_ns.dtsi:69 */
				#size-cells = < 0x1 >;         /* in zephyr/dts/arm/nordic/nrf91_ns.dtsi:70 */

				/* node '/soc/flash-controller@40039000/flash@0/partitions' defined in ../../../../../Users/gok/codex/projects/collar-tracker/firmware/boards/goksel/collar_tracker_r05l/collar-memory.dtsi:14 */
				partitions {
					ranges;                   /* in ../../../../../Users/gok/codex/projects/collar-tracker/firmware/boards/goksel/collar_tracker_r05l/collar-memory.dtsi:15 */
					#address-cells = < 0x1 >; /* in ../../../../../Users/gok/codex/projects/collar-tracker/firmware/boards/goksel/collar_tracker_r05l/collar-memory.dtsi:16 */
					#size-cells = < 0x1 >;    /* in ../../../../../Users/gok/codex/projects/collar-tracker/firmware/boards/goksel/collar_tracker_r05l/collar-memory.dtsi:17 */

					/* node '/soc/flash-controller@40039000/flash@0/partitions/partition@0' defined in ../../../../../Users/gok/codex/projects/collar-tracker/firmware/boards/goksel/collar_tracker_r05l/collar-memory.dtsi:18 */
					slot0_partition: partition@0 {
						compatible = "zephyr,mapped-partition"; /* in ../../../../../Users/gok/codex/projects/collar-tracker/firmware/boards/goksel/collar_tracker_r05l/collar-memory.dtsi:19 */
						label = "image-0";                      /* in ../../../../../Users/gok/codex/projects/collar-tracker/firmware/boards/goksel/collar_tracker_r05l/collar-memory.dtsi:20 */
						reg = < 0x0 0x80000 >;                  /* in ../../../../../Users/gok/codex/projects/collar-tracker/firmware/boards/goksel/collar_tracker_r05l/collar-memory.dtsi:21 */
						ranges = < 0x0 0x0 0x80000 >;           /* in ../../../../../Users/gok/codex/projects/collar-tracker/firmware/boards/goksel/collar_tracker_r05l/collar-memory.dtsi:22 */
						#address-cells = < 0x1 >;               /* in ../../../../../Users/gok/codex/projects/collar-tracker/firmware/boards/goksel/collar_tracker_r05l/collar-memory.dtsi:23 */
						#size-cells = < 0x1 >;                  /* in ../../../../../Users/gok/codex/projects/collar-tracker/firmware/boards/goksel/collar_tracker_r05l/collar-memory.dtsi:24 */

						/* node '/soc/flash-controller@40039000/flash@0/partitions/partition@0/partition@0' defined in ../../../../../Users/gok/codex/projects/collar-tracker/firmware/boards/goksel/collar_tracker_r05l/collar-memory.dtsi:25 */
						slot0_s_partition: partition@0 {
							compatible = "zephyr,mapped-partition"; /* in ../../../../../Users/gok/codex/projects/collar-tracker/firmware/boards/goksel/collar_tracker_r05l/collar-memory.dtsi:26 */
							label = "image-0-secure";               /* in ../../../../../Users/gok/codex/projects/collar-tracker/firmware/boards/goksel/collar_tracker_r05l/collar-memory.dtsi:27 */
							reg = < 0x0 0x40000 >;                  /* in ../../../../../Users/gok/codex/projects/collar-tracker/firmware/boards/goksel/collar_tracker_r05l/collar-memory.dtsi:28 */
						};

						/* node '/soc/flash-controller@40039000/flash@0/partitions/partition@0/partition@40000' defined in ../../../../../Users/gok/codex/projects/collar-tracker/firmware/boards/goksel/collar_tracker_r05l/collar-memory.dtsi:30 */
						slot0_ns_partition: partition@40000 {
							compatible = "zephyr,mapped-partition"; /* in ../../../../../Users/gok/codex/projects/collar-tracker/firmware/boards/goksel/collar_tracker_r05l/collar-memory.dtsi:31 */
							label = "image-0-nonsecure";            /* in ../../../../../Users/gok/codex/projects/collar-tracker/firmware/boards/goksel/collar_tracker_r05l/collar-memory.dtsi:32 */
							reg = < 0x40000 0x40000 >;              /* in ../../../../../Users/gok/codex/projects/collar-tracker/firmware/boards/goksel/collar_tracker_r05l/collar-memory.dtsi:33 */
						};
					};

					/* node '/soc/flash-controller@40039000/flash@0/partitions/partition@f0000' defined in ../../../../../Users/gok/codex/projects/collar-tracker/firmware/boards/goksel/collar_tracker_r05l/collar-memory.dtsi:36 */
					tfm_ps_partition: partition@f0000 {
						compatible = "zephyr,mapped-partition"; /* in ../../../../../Users/gok/codex/projects/collar-tracker/firmware/boards/goksel/collar_tracker_r05l/collar-memory.dtsi:37 */
						label = "tfm-ps";                       /* in ../../../../../Users/gok/codex/projects/collar-tracker/firmware/boards/goksel/collar_tracker_r05l/collar-memory.dtsi:38 */
						reg = < 0xf0000 0x4000 >;               /* in ../../../../../Users/gok/codex/projects/collar-tracker/firmware/boards/goksel/collar_tracker_r05l/collar-memory.dtsi:39 */
					};

					/* node '/soc/flash-controller@40039000/flash@0/partitions/partition@f4000' defined in ../../../../../Users/gok/codex/projects/collar-tracker/firmware/boards/goksel/collar_tracker_r05l/collar-memory.dtsi:41 */
					tfm_its_partition: partition@f4000 {
						compatible = "zephyr,mapped-partition"; /* in ../../../../../Users/gok/codex/projects/collar-tracker/firmware/boards/goksel/collar_tracker_r05l/collar-memory.dtsi:42 */
						label = "tfm-its";                      /* in ../../../../../Users/gok/codex/projects/collar-tracker/firmware/boards/goksel/collar_tracker_r05l/collar-memory.dtsi:43 */
						reg = < 0xf4000 0x2000 >;               /* in ../../../../../Users/gok/codex/projects/collar-tracker/firmware/boards/goksel/collar_tracker_r05l/collar-memory.dtsi:44 */
					};

					/* node '/soc/flash-controller@40039000/flash@0/partitions/partition@f6000' defined in ../../../../../Users/gok/codex/projects/collar-tracker/firmware/boards/goksel/collar_tracker_r05l/collar-memory.dtsi:46 */
					tfm_otp_partition: partition@f6000 {
						compatible = "zephyr,mapped-partition"; /* in ../../../../../Users/gok/codex/projects/collar-tracker/firmware/boards/goksel/collar_tracker_r05l/collar-memory.dtsi:47 */
						label = "tfm-otp";                      /* in ../../../../../Users/gok/codex/projects/collar-tracker/firmware/boards/goksel/collar_tracker_r05l/collar-memory.dtsi:48 */
						reg = < 0xf6000 0x2000 >;               /* in ../../../../../Users/gok/codex/projects/collar-tracker/firmware/boards/goksel/collar_tracker_r05l/collar-memory.dtsi:49 */
					};

					/* node '/soc/flash-controller@40039000/flash@0/partitions/partition@f8000' defined in ../../../../../Users/gok/codex/projects/collar-tracker/firmware/boards/goksel/collar_tracker_r05l/collar-memory.dtsi:51 */
					storage_partition: partition@f8000 {
						compatible = "zephyr,mapped-partition"; /* in ../../../../../Users/gok/codex/projects/collar-tracker/firmware/boards/goksel/collar_tracker_r05l/collar-memory.dtsi:52 */
						label = "storage";                      /* in ../../../../../Users/gok/codex/projects/collar-tracker/firmware/boards/goksel/collar_tracker_r05l/collar-memory.dtsi:53 */
						reg = < 0xf8000 0x8000 >;               /* in ../../../../../Users/gok/codex/projects/collar-tracker/firmware/boards/goksel/collar_tracker_r05l/collar-memory.dtsi:54 */
					};
				};
			};
		};

		/* node '/soc/gpiote@40031000' defined in zephyr/dts/arm/nordic/nrf91_ns.dtsi:79 */
		gpiote: gpiote1: gpiote@40031000 {
			compatible = "nordic,nrf-gpiote"; /* in zephyr/dts/arm/nordic/nrf91_ns.dtsi:80 */
			reg = < 0x40031000 0x1000 >;      /* in zephyr/dts/arm/nordic/nrf91_ns.dtsi:81 */
			interrupts = < 0x31 0x5 >;        /* in zephyr/dts/arm/nordic/nrf91_ns.dtsi:82 */
			instance = < 0x1 >;               /* in zephyr/dts/arm/nordic/nrf91_ns.dtsi:84 */
			status = "okay";                  /* in ../../../../../Users/gok/codex/projects/collar-tracker/firmware/boards/goksel/collar_tracker_r05l/collar_tracker_r05l_nrf9151_ns.dts:24 */
			phandle = < 0x5 >;                /* in zephyr/dts/arm/nordic/nrf91_peripherals.dtsi:303 */
		};
	};

	/* node '/pin-controller' defined in zephyr/dts/vendor/nordic/nrf_common.dtsi:26 */
	pinctrl: pin-controller {
		compatible = "nordic,nrf-pinctrl"; /* in zephyr/dts/vendor/nordic/nrf_common.dtsi:31 */

		/* node '/pin-controller/board-i2c-default' defined in ../../../../../Users/gok/codex/projects/collar-tracker/firmware/boards/goksel/collar_tracker_r05l/collar_tracker_r05l_nrf9151_ns.dts:27 */
		board_i2c_default: board-i2c-default {
			phandle = < 0x2 >; /* in ../../../../../Users/gok/codex/projects/collar-tracker/firmware/boards/goksel/collar_tracker_r05l/collar_tracker_r05l_nrf9151_ns.dts:44 */

			/* node '/pin-controller/board-i2c-default/group1' defined in ../../../../../Users/gok/codex/projects/collar-tracker/firmware/boards/goksel/collar_tracker_r05l/collar_tracker_r05l_nrf9151_ns.dts:28 */
			group1 {
				psels = < 0xc000000 >,
				        < 0xb000001 >; /* in ../../../../../Users/gok/codex/projects/collar-tracker/firmware/boards/goksel/collar_tracker_r05l/collar_tracker_r05l_nrf9151_ns.dts:28 */
			};
		};

		/* node '/pin-controller/board-i2c-sleep' defined in ../../../../../Users/gok/codex/projects/collar-tracker/firmware/boards/goksel/collar_tracker_r05l/collar_tracker_r05l_nrf9151_ns.dts:30 */
		board_i2c_sleep: board-i2c-sleep {
			phandle = < 0x3 >; /* in ../../../../../Users/gok/codex/projects/collar-tracker/firmware/boards/goksel/collar_tracker_r05l/collar_tracker_r05l_nrf9151_ns.dts:45 */

			/* node '/pin-controller/board-i2c-sleep/group1' defined in ../../../../../Users/gok/codex/projects/collar-tracker/firmware/boards/goksel/collar_tracker_r05l/collar_tracker_r05l_nrf9151_ns.dts:31 */
			group1 {
				psels = < 0xc000000 >,
				        < 0xb000001 >; /* in ../../../../../Users/gok/codex/projects/collar-tracker/firmware/boards/goksel/collar_tracker_r05l/collar_tracker_r05l_nrf9151_ns.dts:32 */
				low-power-enable;      /* in ../../../../../Users/gok/codex/projects/collar-tracker/firmware/boards/goksel/collar_tracker_r05l/collar_tracker_r05l_nrf9151_ns.dts:33 */
			};
		};
	};

	/* node '/entropy_bt_hci' defined in zephyr/dts/vendor/nordic/nrf_common.dtsi:34 */
	rng_hci: entropy_bt_hci {
		compatible = "zephyr,bt-hci-entropy"; /* in zephyr/dts/vendor/nordic/nrf_common.dtsi:35 */
		status = "disabled";                  /* in zephyr/dts/vendor/nordic/nrf_common.dtsi:36 */
	};

	/* node '/sw-pwm' defined in zephyr/dts/vendor/nordic/nrf_common.dtsi:39 */
	sw_pwm: sw-pwm {
		compatible = "nordic,nrf-sw-pwm"; /* in zephyr/dts/vendor/nordic/nrf_common.dtsi:40 */
		status = "disabled";              /* in zephyr/dts/vendor/nordic/nrf_common.dtsi:41 */
		generator = < &timer1 >;          /* in zephyr/dts/vendor/nordic/nrf_common.dtsi:42 */
		clock-prescaler = < 0x0 >;        /* in zephyr/dts/vendor/nordic/nrf_common.dtsi:43 */
		#pwm-cells = < 0x3 >;             /* in zephyr/dts/vendor/nordic/nrf_common.dtsi:44 */
	};

	/* node '/cpus' defined in zephyr/dts/arm/nordic/nrf91_ns.dtsi:12 */
	cpus {
		#address-cells = < 0x1 >; /* in zephyr/dts/arm/nordic/nrf91_ns.dtsi:13 */
		#size-cells = < 0x0 >;    /* in zephyr/dts/arm/nordic/nrf91_ns.dtsi:14 */

		/* node '/cpus/cpu@0' defined in zephyr/dts/arm/nordic/nrf91_ns.dtsi:16 */
		cpu@0 {
			device_type = "cpu";            /* in zephyr/dts/arm/nordic/nrf91_ns.dtsi:17 */
			compatible = "arm,cortex-m33f"; /* in zephyr/dts/arm/nordic/nrf91_ns.dtsi:18 */
			reg = < 0x0 >;                  /* in zephyr/dts/arm/nordic/nrf91_ns.dtsi:19 */
			#address-cells = < 0x1 >;       /* in zephyr/dts/arm/nordic/nrf91_ns.dtsi:20 */
			#size-cells = < 0x1 >;          /* in zephyr/dts/arm/nordic/nrf91_ns.dtsi:21 */

			/* node '/cpus/cpu@0/mpu@e000ed90' defined in zephyr/dts/arm/nordic/nrf91_ns.dtsi:23 */
			mpu: mpu@e000ed90 {
				compatible = "arm,armv8m-mpu"; /* in zephyr/dts/arm/nordic/nrf91_ns.dtsi:24 */
				reg = < 0xe000ed90 0x40 >;     /* in zephyr/dts/arm/nordic/nrf91_ns.dtsi:25 */
			};
		};
	};

	/* node '/psa-rng' defined in zephyr/dts/arm/nordic/nrf91_ns.dtsi:88 */
	psa_rng: psa-rng {
		compatible = "zephyr,psa-crypto-rng"; /* in zephyr/dts/arm/nordic/nrf91_ns.dtsi:89 */
		status = "okay";                      /* in zephyr/dts/arm/nordic/nrf91_ns.dtsi:90 */
	};

	/* node '/board-io' defined in ../../../../../Users/gok/codex/projects/collar-tracker/firmware/boards/goksel/collar_tracker_r05l/collar_tracker_r05l_nrf9151_ns.dts:14 */
	board_io: board-io {
		compatible = "goksel,collar-r05l-io";     /* in ../../../../../Users/gok/codex/projects/collar-tracker/firmware/boards/goksel/collar_tracker_r05l/collar_tracker_r05l_nrf9151_ns.dts:15 */
		charge-status-gpios = < &gpio0 0xa 0x1 >; /* in ../../../../../Users/gok/codex/projects/collar-tracker/firmware/boards/goksel/collar_tracker_r05l/collar_tracker_r05l_nrf9151_ns.dts:16 */
		charge-fault-gpios = < &gpio0 0xb 0x1 >;  /* in ../../../../../Users/gok/codex/projects/collar-tracker/firmware/boards/goksel/collar_tracker_r05l/collar_tracker_r05l_nrf9151_ns.dts:17 */
		fuel-alert-gpios = < &gpio0 0xd 0x1 >;    /* in ../../../../../Users/gok/codex/projects/collar-tracker/firmware/boards/goksel/collar_tracker_r05l/collar_tracker_r05l_nrf9151_ns.dts:18 */
		health-enable-gpios = < &gpio0 0x9 0x0 >; /* in ../../../../../Users/gok/codex/projects/collar-tracker/firmware/boards/goksel/collar_tracker_r05l/collar_tracker_r05l_nrf9151_ns.dts:19 */
	};
};
